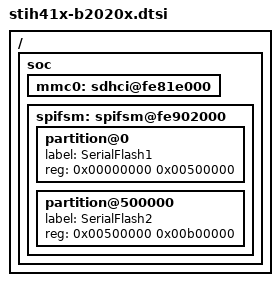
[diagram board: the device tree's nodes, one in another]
/*
 * Copyright (C) 2013 STMicroelectronics (R&D) Limited.
 * Author: Lee Jones <lee.jones@linaro.org>
 *
 * This program is free software; you can redistribute it and/or modify
 * it under the terms of the GNU General Public License version 2 as
 * publishhed by the Free Software Foundation.
 */
/ {
	soc {
		mmc0: sdhci@fe81e000 {
			status = "okay";
		};

		spifsm: spifsm@fe902000 {
			#address-cells = <1>;
			#size-cells    = <1>;

			status = "okay";

			partition@0 {
				label = "SerialFlash1";
				reg   = <0x00000000 0x00500000>;
			};

			partition@500000 {
				label = "SerialFlash2";
				reg   = <0x00500000 0x00b00000>;
			};
		};
	};
};
